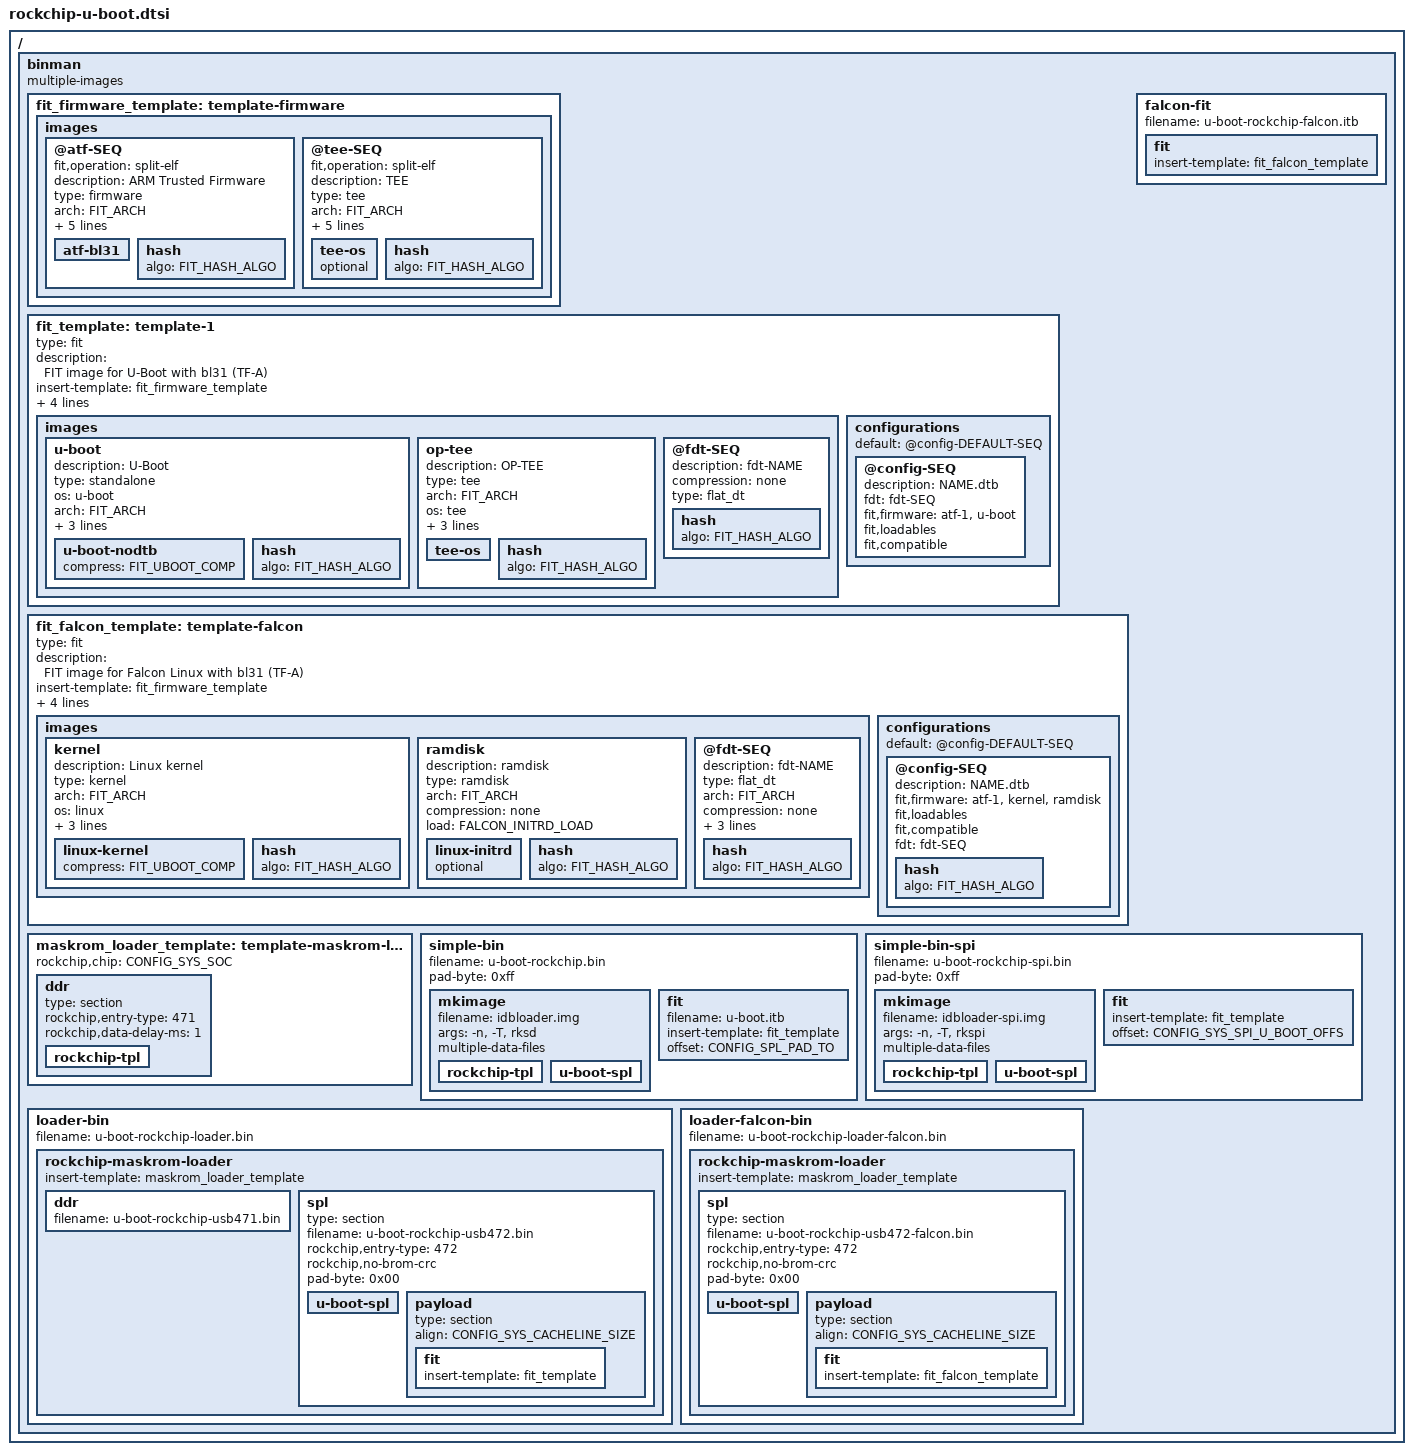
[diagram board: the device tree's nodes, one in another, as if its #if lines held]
// SPDX-License-Identifier: GPL-2.0+
/*
 * Copyright (C) 2019 Jagan Teki <jagan@amarulasolutions.com>
 */

#include <config.h>

#ifdef CONFIG_ARM64
#define FIT_ARCH		"arm64"
#else
#define FIT_ARCH		"arm"
#endif

#if defined(CONFIG_SPL_GZIP)
#define FIT_UBOOT_COMP		"gzip"
#elif defined(CONFIG_SPL_LZMA)
#define FIT_UBOOT_COMP		"lzma"
#else
#define FIT_UBOOT_COMP		"none"
#endif

/*
 * SHA256 should be enabled in SPL when signature validation is involved,
 * CRC32 should only be used for basic checksum validation of FIT images.
 */
#if defined(CONFIG_SPL_FIT_SIGNATURE)
#if defined(CONFIG_SPL_SHA256)
#define FIT_HASH_ALGO		"sha256"
#elif defined(CONFIG_SPL_CRC32)
#define FIT_HASH_ALGO		"crc32"
#endif
#endif

#if defined(CONFIG_SPL_FIT) && (defined(CONFIG_ARM64) || defined(CONFIG_SPL_OPTEE_IMAGE))
#define HAS_FIT
#endif

#ifdef CONFIG_ROCKCHIP_FALCON_IMAGE
/* Falcon-mode load addresses, relative to the SoC DRAM base. */
#define FALCON_KERNEL_LOAD \
	(CFG_SYS_SDRAM_BASE + CONFIG_ROCKCHIP_FALCON_KERNEL_LOAD)
#define FALCON_FDT_LOAD \
	(CFG_SYS_SDRAM_BASE + CONFIG_ROCKCHIP_FALCON_FDT_LOAD)
#define FALCON_INITRD_LOAD \
	(CFG_SYS_SDRAM_BASE + CONFIG_ROCKCHIP_FALCON_INITRD_LOAD)
#endif

/ {
	binman: binman {
		multiple-images;
	};
};

#ifdef CONFIG_SPL
&binman {
#ifdef HAS_FIT
#ifdef CONFIG_ARM64
	/*
	 * Shared ARM Trusted Firmware (BL31) and optional OP-TEE split-elf
	 * images, reused by both the U-Boot and Falcon Linux FIT templates.
	 */
	fit_firmware_template: template-firmware {
		images {
			@atf-SEQ {
				fit,operation = "split-elf";
				description = "ARM Trusted Firmware";
				type = "firmware";
				arch = FIT_ARCH;
				os = "arm-trusted-firmware";
				compression = "none";
				fit,load;
				fit,entry;
				fit,data;

				atf-bl31 {
				};
#ifdef FIT_HASH_ALGO
				hash {
					algo = FIT_HASH_ALGO;
				};
#endif
			};
			@tee-SEQ {
				fit,operation = "split-elf";
				description = "TEE";
				type = "tee";
				arch = FIT_ARCH;
				os = "tee";
				compression = "none";
				fit,load;
				fit,entry;
				fit,data;

				tee-os {
					optional;
				};
#ifdef FIT_HASH_ALGO
				hash {
					algo = FIT_HASH_ALGO;
				};
#endif
			};
		};
	};
#endif /* CONFIG_ARM64 */

	fit_template: template-1 {
		type = "fit";
#ifdef CONFIG_ARM64
		description = "FIT image for U-Boot with bl31 (TF-A)";
		insert-template = <&fit_firmware_template>;
#else
		description = "FIT image with OP-TEE";
#endif
		#address-cells = <1>;
		fit,fdt-list = "of-list";
		fit,external-offset = <CONFIG_FIT_EXTERNAL_OFFSET>;
		fit,align = <512>;
		images {
			u-boot {
				description = "U-Boot";
				type = "standalone";
				os = "u-boot";
				arch = FIT_ARCH;
				compression = FIT_UBOOT_COMP;
				load = <CONFIG_TEXT_BASE>;
				entry = <CONFIG_TEXT_BASE>;
				u-boot-nodtb {
					compress = FIT_UBOOT_COMP;
				};
#ifdef FIT_HASH_ALGO
				hash {
					algo = FIT_HASH_ALGO;
				};
#endif
			};

#ifndef CONFIG_ARM64
			op-tee {
				description = "OP-TEE";
				type = "tee";
				arch = FIT_ARCH;
				os = "tee";
				compression = "none";
				load = <(CFG_SYS_SDRAM_BASE + 0x8400000)>;
				entry = <(CFG_SYS_SDRAM_BASE + 0x8400000)>;

				tee-os {
				};
#ifdef FIT_HASH_ALGO
				hash {
					algo = FIT_HASH_ALGO;
				};
#endif
			};
#endif /* !CONFIG_ARM64 */

			@fdt-SEQ {
				description = "fdt-NAME";
				compression = "none";
				type = "flat_dt";
#ifdef FIT_HASH_ALGO
				hash {
					algo = FIT_HASH_ALGO;
				};
#endif
			};
		};

		configurations {
			default = "@config-DEFAULT-SEQ";
			@config-SEQ {
				description = "NAME.dtb";
				fdt = "fdt-SEQ";
#ifdef CONFIG_ARM64
				fit,firmware = "atf-1", "u-boot";
#else
				fit,firmware = "op-tee", "u-boot";
#endif
				fit,loadables;
				fit,compatible;
			};
		};
	};

#ifdef CONFIG_ROCKCHIP_FALCON_IMAGE
	fit_falcon_template: template-falcon {
		type = "fit";
		description = "FIT image for Falcon Linux with bl31 (TF-A)";
		insert-template = <&fit_firmware_template>;
		#address-cells = <1>;
		fit,fdt-list = "of-list";
		fit,external-offset = <CONFIG_FIT_EXTERNAL_OFFSET>;
		fit,align = <512>;

		images {
			kernel {
				description = "Linux kernel";
				type = "kernel";
				arch = FIT_ARCH;
				os = "linux";
				compression = FIT_UBOOT_COMP;
				load = <FALCON_KERNEL_LOAD>;
				entry = <FALCON_KERNEL_LOAD>;

				linux-kernel {
					compress = FIT_UBOOT_COMP;
				};
#ifdef FIT_HASH_ALGO
				hash {
					algo = FIT_HASH_ALGO;
				};
#endif
			};

			ramdisk {
				description = "ramdisk";
				type = "ramdisk";
				arch = FIT_ARCH;
				compression = "none";
				load = <FALCON_INITRD_LOAD>;

				linux-initrd {
					optional;
				};
#ifdef FIT_HASH_ALGO
				hash {
					algo = FIT_HASH_ALGO;
				};
#endif
			};

			@fdt-SEQ {
				description = "fdt-NAME";
				type = "flat_dt";
				arch = FIT_ARCH;
				compression = "none";
				load = <FALCON_FDT_LOAD>;
#ifdef CONFIG_USE_BOOTARGS
				fit,bootargs = CONFIG_BOOTARGS;
#endif
				fit,initrd = "ramdisk";
#ifdef FIT_HASH_ALGO
				hash {
					algo = FIT_HASH_ALGO;
				};
#endif
			};
		};

		configurations {
			default = "@config-DEFAULT-SEQ";
			@config-SEQ {
				description = "NAME.dtb";
				fit,firmware = "atf-1", "kernel", "ramdisk";
				fit,loadables;
				fit,compatible;
				fdt = "fdt-SEQ";
#ifdef FIT_HASH_ALGO
				hash {
					algo = FIT_HASH_ALGO;
				};
#endif
			};
		};
	};

	falcon-fit {
		filename = "u-boot-rockchip-falcon.itb";

		fit {
			insert-template = <&fit_falcon_template>;
		};
	};
#endif
#endif /* HAS_FIT */

#ifdef CONFIG_ROCKCHIP_MASKROM_IMAGE
	/*
	 * The parts every maskrom loader image shares: the properties of the
	 * loader itself, and the code 471 payload which the BootROM loads into
	 * SRAM and runs to bring up DRAM.
	 *
	 * rockchip,chip is the name boot_merger records. For most SoCs that is
	 * CONFIG_SYS_SOC, but one whose name differs (rk3399 calls itself
	 * RK330C) can set the property in its own loader node to override this.
	 */
	maskrom_loader_template: template-maskrom-loader {
		rockchip,chip = CONFIG_SYS_SOC;

		ddr {
			type = "section";
			rockchip,entry-type = "471";
			rockchip,data-delay-ms = <1>;

#ifdef CONFIG_ROCKCHIP_EXTERNAL_TPL
			rockchip-tpl {
			};
#elif defined(CONFIG_TPL)
			u-boot-tpl {
				no-write-symbols;
			};
#endif
		};
	};
#endif /* CONFIG_ROCKCHIP_MASKROM_IMAGE */

	simple-bin {
		filename = "u-boot-rockchip.bin";
		pad-byte = <0xff>;

		mkimage {
			filename = "idbloader.img";
			args = "-n", CONFIG_SYS_SOC, "-T", "rksd";
			multiple-data-files;

#ifdef CONFIG_ROCKCHIP_EXTERNAL_TPL
			rockchip-tpl {
			};
#elif defined(CONFIG_TPL)
			u-boot-tpl {
			};
#endif
			u-boot-spl {
			};
		};

#ifdef HAS_FIT
		fit {
			filename = "u-boot.itb";
			insert-template = <&fit_template>;
#else
		u-boot-img {
#endif
			offset = <CONFIG_SPL_PAD_TO>;
		};
	};

#ifdef CONFIG_ROCKCHIP_SPI_IMAGE
	simple-bin-spi {
		filename = "u-boot-rockchip-spi.bin";
		pad-byte = <0xff>;

		mkimage {
			filename = "idbloader-spi.img";
			args = "-n", CONFIG_SYS_SOC, "-T", "rkspi";
			multiple-data-files;

#ifdef CONFIG_ROCKCHIP_EXTERNAL_TPL
			rockchip-tpl {
			};
#elif defined(CONFIG_TPL)
			u-boot-tpl {
			};
#endif
			u-boot-spl {
			};
		};

#ifdef HAS_FIT
		fit {
			insert-template = <&fit_template>;
#else
		u-boot-img {
#endif
			/* Sync with u-boot,spl-payload-offset if present */
			offset = <CONFIG_SYS_SPI_U_BOOT_OFFS>;
		};
	};
#endif /* CONFIG_ROCKCHIP_SPI_IMAGE */

#ifdef CONFIG_ROCKCHIP_MASKROM_IMAGE
	loader-bin {
		filename = "u-boot-rockchip-loader.bin";

		rockchip-maskrom-loader {
			insert-template = <&maskrom_loader_template>;

			/* Write the shared code 471 payload out on its own */
			ddr {
				filename = "u-boot-rockchip-usb471.bin";
			};

			spl {
				type = "section";
				filename = "u-boot-rockchip-usb472.bin";
				rockchip,entry-type = "472";
#ifdef CONFIG_ROCKCHIP_MASKROM_NO_BROM_CRC
				rockchip,no-brom-crc;
#endif
				pad-byte = <0x00>;

				u-boot-spl {
				};

				payload {
					type = "section";
					align = <CONFIG_SYS_CACHELINE_SIZE>;
#ifdef HAS_FIT
				fit {
					insert-template = <&fit_template>;
#else
				u-boot-img {
#endif
				};
				};
			};
		};
	};

#ifdef CONFIG_ROCKCHIP_FALCON_IMAGE
	loader-falcon-bin {
		filename = "u-boot-rockchip-loader-falcon.bin";

		rockchip-maskrom-loader {
			insert-template = <&maskrom_loader_template>;

			spl {
				type = "section";
				filename = "u-boot-rockchip-usb472-falcon.bin";
				rockchip,entry-type = "472";
#ifdef CONFIG_ROCKCHIP_MASKROM_NO_BROM_CRC
				rockchip,no-brom-crc;
#endif
				pad-byte = <0x00>;

				u-boot-spl {
				};

				payload {
					type = "section";
					align = <CONFIG_SYS_CACHELINE_SIZE>;

					fit {
						insert-template = <&fit_falcon_template>;
					};
				};
			};
		};
	};
#endif
#endif /* CONFIG_ROCKCHIP_MASKROM_IMAGE */
};
#endif /* CONFIG_SPL */
